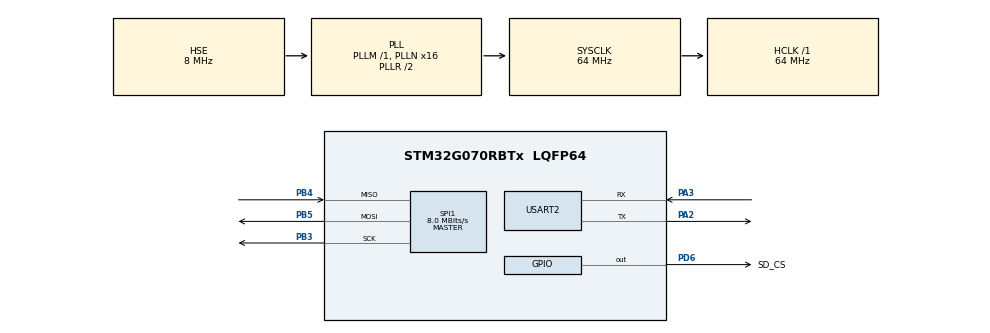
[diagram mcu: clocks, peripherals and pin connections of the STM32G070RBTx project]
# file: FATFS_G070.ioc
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FATFS.BOARD_NAME=stm32g070rb
FATFS.DISKIO_CODE=1
Mcu.Family=STM32G0
Mcu.Name=STM32G070RBTx
Mcu.Package=LQFP64
PA13.GPIO_Label=TMS
PA13.Mode=Serial_Wire
PA13.Signal=SYS_SWDIO
PA14-BOOT0.GPIO_Label=TCK
PA14-BOOT0.Mode=Serial_Wire
PA14-BOOT0.Signal=SYS_SWCLK
PA2.Mode=Asynchronous
PA2.Signal=USART2_TX
PA3.Mode=Asynchronous
PA3.Signal=USART2_RX
PB3.Mode=Full_Duplex_Master
PB3.Signal=SPI1_SCK
PB4.Mode=Full_Duplex_Master
PB4.Signal=SPI1_MISO
PB5.Mode=Full_Duplex_Master
PB5.Signal=SPI1_MOSI
PC13.Mode=SYS_WakeUp1
PC13.Signal=SYS_WKUP2
PC14-OSC32_IN\ (PC14).Mode=LSE-External-Oscillator
PC14-OSC32_IN\ (PC14).Signal=RCC_OSC32_IN
PC15-OSC32_OUT\ (PC15).Mode=LSE-External-Oscillator
PC15-OSC32_OUT\ (PC15).Signal=RCC_OSC32_OUT
PD6.GPIO_Label=SD_CS
PD6.Signal=GPIO_Output
PF0-OSC_IN\ (PF0).GPIO_Label=MCO
PF0-OSC_IN\ (PF0).Mode=HSE-External-Clock-Source
PF0-OSC_IN\ (PF0).Signal=RCC_OSC_IN
ProjectManager.HeapSize=0x200
ProjectManager.StackSize=0x400
ProjectManager.TargetToolchain=TrueSTUDIO
RCC.ADCFreq_Value=64000000
RCC.AHBFreq_Value=64000000
RCC.APB1CLKDivider=RCC_HCLK_DIV2
RCC.CortexFreq_Value=64000000
RCC.EXTERNAL_CLOCK_VALUE=12288000
RCC.HCLKFreq_Value=64000000
RCC.HSE_VALUE=8000000
RCC.HSI_VALUE=16000000
RCC.PLLN=16
RCC.PLLSourceVirtual=RCC_PLLSOURCE_HSE
RCC.RTCClockSelection=RCC_RTCCLKSOURCE_LSE
RCC.SYSCLKFreq_VALUE=64000000
RCC.SYSCLKSource=RCC_SYSCLKSOURCE_PLLCLK
RCC.VCOOutputFreq_Value=128000000
SPI1.BaudRatePrescaler=SPI_BAUDRATEPRESCALER_4
SPI1.CalculateBaudRate=8.0 MBits/s
SPI1.DataSize=SPI_DATASIZE_8BIT
SPI1.Direction=SPI_DIRECTION_2LINES
SPI1.Mode=SPI_MODE_MASTER
SPI1.VirtualType=VM_MASTER
USART2.VirtualMode-Asynchronous=VM_ASYNC
VP_FATFS_VS_Generic.Mode=User_defined
VP_RTC_VS_RTC_Activate.Mode=RTC_Enabled
VP_SYS_VS_DBSignals.Mode=DisableDeadBatterySignals
board=NUCLEO-G070RB

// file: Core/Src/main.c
/* USER CODE BEGIN Header */
/**
  ******************************************************************************
  * @file           : main.c
  * @brief          : Main program body
  ******************************************************************************
  * @attention
  *
  * <h2><center>&copy; Copyright (c) 2019 STMicroelectronics.
  * All rights reserved.</center></h2>
  *
  * This software component is licensed by ST under Ultimate Liberty license
  * SLA0044, the "License"; You may not use this file except in compliance with
  * the License. You may obtain a copy of the License at:
  *                             www.st.com/SLA0044
  *
  ******************************************************************************
  */
/* USER CODE END Header */

#include "main.h"
#include "app_fatfs.h"

/* USER CODE BEGIN Includes */
#include "lvgl/lvgl.h"
/* USER CODE END Includes */

/* USER CODE BEGIN PTD */
static lv_disp_buf_t disp_buf;
static lv_color_t buf[LV_HOR_RES_MAX * 10];		// Declare a buffer for 10 lines
/* USER CODE END PTD */

RTC_HandleTypeDef hrtc;

SPI_HandleTypeDef hspi1;

UART_HandleTypeDef huart2;

void SystemClock_Config(void);
static void MX_GPIO_Init(void);
static void MX_RTC_Init(void);
static void MX_SPI1_Init(void);
static void MX_USART2_UART_Init(void);

int main(void)
{

  /* MCU Configuration--------------------------------------------------------*/

  /* Reset of all peripherals, Initializes the Flash interface and the Systick. */
  HAL_Init();

  /* Configure the system clock */
  SystemClock_Config();

  /* Initialize all configured peripherals */
  MX_GPIO_Init();
  MX_RTC_Init();
  MX_SPI1_Init();
  MX_USART2_UART_Init();
  if (MX_FATFS_Init() != APP_OK) {
    Error_Handler();
  }
  /* USER CODE BEGIN 2 */
  //lv_disp_buf_init(&disp_buf, buf, buf2, LV_HOR_RES_MAX * 10);    //Initialize the display buffer
  lv_disp_buf_init(&disp_buf, buf, NULL, LV_HOR_RES_MAX * 10);    //Initialize the display buffer
  //lv_log_register_print_cb(my_print);
  lv_init();
  /* USER CODE END 2 */

  /* Infinite loop */
  while (1)
  {

    /* USER CODE BEGIN 3 */
	  // Eventos da GUI LittleVG
	  lv_task_handler();
  }
  /* USER CODE END 3 */
}

void SystemClock_Config(void)
{
  RCC_OscInitTypeDef RCC_OscInitStruct = {0};
  RCC_ClkInitTypeDef RCC_ClkInitStruct = {0};
  RCC_PeriphCLKInitTypeDef PeriphClkInit = {0};

  /** Configure the main internal regulator output voltage
  */
  HAL_PWREx_ControlVoltageScaling(PWR_REGULATOR_VOLTAGE_SCALE1);
  /** Configure LSE Drive Capability
  */
  __HAL_RCC_LSEDRIVE_CONFIG(RCC_LSEDRIVE_LOW);
  /** Initializes the CPU, AHB and APB busses clocks
  */
  RCC_OscInitStruct.OscillatorType = RCC_OSCILLATORTYPE_HSE|RCC_OSCILLATORTYPE_LSE;
  RCC_OscInitStruct.HSEState = RCC_HSE_BYPASS;
  RCC_OscInitStruct.LSEState = RCC_LSE_ON;
  RCC_OscInitStruct.PLL.PLLState = RCC_PLL_ON;
  RCC_OscInitStruct.PLL.PLLSource = RCC_PLLSOURCE_HSE;
  RCC_OscInitStruct.PLL.PLLM = RCC_PLLM_DIV1;
  RCC_OscInitStruct.PLL.PLLN = 16;
  RCC_OscInitStruct.PLL.PLLP = RCC_PLLP_DIV2;
  RCC_OscInitStruct.PLL.PLLR = RCC_PLLR_DIV2;
  if (HAL_RCC_OscConfig(&RCC_OscInitStruct) != HAL_OK)
  {
    Error_Handler();
  }
  /** Initializes the CPU, AHB and APB busses clocks
  */
  RCC_ClkInitStruct.ClockType = RCC_CLOCKTYPE_HCLK|RCC_CLOCKTYPE_SYSCLK
                              |RCC_CLOCKTYPE_PCLK1;
  RCC_ClkInitStruct.SYSCLKSource = RCC_SYSCLKSOURCE_PLLCLK;
  RCC_ClkInitStruct.AHBCLKDivider = RCC_SYSCLK_DIV1;
  RCC_ClkInitStruct.APB1CLKDivider = RCC_HCLK_DIV2;

  if (HAL_RCC_ClockConfig(&RCC_ClkInitStruct, FLASH_LATENCY_2) != HAL_OK)
  {
    Error_Handler();
  }
  /** Initializes the peripherals clocks
  */
  PeriphClkInit.PeriphClockSelection = RCC_PERIPHCLK_RTC|RCC_PERIPHCLK_USART2;
  PeriphClkInit.Usart2ClockSelection = RCC_USART2CLKSOURCE_PCLK1;
  PeriphClkInit.RTCClockSelection = RCC_RTCCLKSOURCE_LSE;

  if (HAL_RCCEx_PeriphCLKConfig(&PeriphClkInit) != HAL_OK)
  {
    Error_Handler();
  }
}

static void MX_RTC_Init(void)
{

  /** Initialize RTC Only
  */
  hrtc.Instance = RTC;
  hrtc.Init.HourFormat = RTC_HOURFORMAT_24;
  hrtc.Init.AsynchPrediv = 127;
  hrtc.Init.SynchPrediv = 255;
  hrtc.Init.OutPut = RTC_OUTPUT_DISABLE;
  hrtc.Init.OutPutRemap = RTC_OUTPUT_REMAP_NONE;
  hrtc.Init.OutPutPolarity = RTC_OUTPUT_POLARITY_HIGH;
  hrtc.Init.OutPutType = RTC_OUTPUT_TYPE_OPENDRAIN;
  hrtc.Init.OutPutPullUp = RTC_OUTPUT_PULLUP_NONE;
  if (HAL_RTC_Init(&hrtc) != HAL_OK)
  {
    Error_Handler();
  }

}

static void MX_SPI1_Init(void)
{

  /* SPI1 parameter configuration*/
  hspi1.Instance = SPI1;
  hspi1.Init.Mode = SPI_MODE_MASTER;
  hspi1.Init.Direction = SPI_DIRECTION_2LINES;
  hspi1.Init.DataSize = SPI_DATASIZE_8BIT;
  hspi1.Init.CLKPolarity = SPI_POLARITY_LOW;
  hspi1.Init.CLKPhase = SPI_PHASE_1EDGE;
  hspi1.Init.NSS = SPI_NSS_SOFT;
  hspi1.Init.BaudRatePrescaler = SPI_BAUDRATEPRESCALER_4;
  hspi1.Init.FirstBit = SPI_FIRSTBIT_MSB;
  hspi1.Init.TIMode = SPI_TIMODE_DISABLE;
  hspi1.Init.CRCCalculation = SPI_CRCCALCULATION_DISABLE;
  hspi1.Init.CRCPolynomial = 7;
  hspi1.Init.CRCLength = SPI_CRC_LENGTH_DATASIZE;
  hspi1.Init.NSSPMode = SPI_NSS_PULSE_ENABLE;
  if (HAL_SPI_Init(&hspi1) != HAL_OK)
  {
    Error_Handler();
  }

}

static void MX_USART2_UART_Init(void)
{

  huart2.Instance = USART2;
  huart2.Init.BaudRate = 115200;
  huart2.Init.WordLength = UART_WORDLENGTH_7B;
  huart2.Init.StopBits = UART_STOPBITS_1;
  huart2.Init.Parity = UART_PARITY_NONE;
  huart2.Init.Mode = UART_MODE_TX_RX;
  huart2.Init.HwFlowCtl = UART_HWCONTROL_NONE;
  huart2.Init.OverSampling = UART_OVERSAMPLING_16;
  huart2.Init.OneBitSampling = UART_ONE_BIT_SAMPLE_DISABLE;
  huart2.Init.ClockPrescaler = UART_PRESCALER_DIV1;
  huart2.AdvancedInit.AdvFeatureInit = UART_ADVFEATURE_NO_INIT;
  if (HAL_UART_Init(&huart2) != HAL_OK)
  {
    Error_Handler();
  }
  if (HAL_UARTEx_SetTxFifoThreshold(&huart2, UART_TXFIFO_THRESHOLD_1_8) != HAL_OK)
  {
    Error_Handler();
  }
  if (HAL_UARTEx_SetRxFifoThreshold(&huart2, UART_RXFIFO_THRESHOLD_1_8) != HAL_OK)
  {
    Error_Handler();
  }
  if (HAL_UARTEx_DisableFifoMode(&huart2) != HAL_OK)
  {
    Error_Handler();
  }

}

static void MX_GPIO_Init(void)
{
  GPIO_InitTypeDef GPIO_InitStruct = {0};

  /* GPIO Ports Clock Enable */
  __HAL_RCC_GPIOC_CLK_ENABLE();
  __HAL_RCC_GPIOF_CLK_ENABLE();
  __HAL_RCC_GPIOA_CLK_ENABLE();
  __HAL_RCC_GPIOD_CLK_ENABLE();
  __HAL_RCC_GPIOB_CLK_ENABLE();

  /*Configure GPIO pin Output Level */
  HAL_GPIO_WritePin(SD_CS_GPIO_Port, SD_CS_Pin, GPIO_PIN_RESET);

  /*Configure GPIO pin : SD_CS_Pin */
  GPIO_InitStruct.Pin = SD_CS_Pin;
  GPIO_InitStruct.Mode = GPIO_MODE_OUTPUT_PP;
  GPIO_InitStruct.Pull = GPIO_NOPULL;
  GPIO_InitStruct.Speed = GPIO_SPEED_FREQ_LOW;
  HAL_GPIO_Init(SD_CS_GPIO_Port, &GPIO_InitStruct);

}

void Error_Handler(void)
{
}

/************************ (C) COPYRIGHT STMicroelectronics *****END OF FILE****/
